# CM33 register map
Registers are 32-bit, read-write, reset 0x0 unless marked. A register's access mark holds for its fields unless they carry their own. Offsets are from the block's base; lines under a group give offsets from that group; [hi:lo] are bit positions; {n}, {i} and the like mark numbered series; 'fields as' and 'values as' point back to an identical list; <NAME> marks a mode.

## Memory map
0xE0001000 DWT size 0x8 — Data Watchpoint and Trace
0xE000E010 SYSTICK size 0x20 — SysTick Timer
0xE000E100 NVIC size 0x380 — Nested Vectored Interrupt Controller
0xE000ED00 SCB size 0x90 — System Control Block
0xE000ED90 MPU size 0x38 — Memory Protection Unit (PMSAv8)
0xE000EDD0 SAU blocks up to offset 0x1C — Security Attribution Unit (fault registers)
0xE000EDF0 DCB size 0x10 — Debug Control Block
0xE000EF34 FP size 0x4 — Floating-Point Extension
0xE000EF50 CMO size 0x2C — Cache Maintenance Operations

## SYSTICK — SysTick Timer
Base 0xE000E010
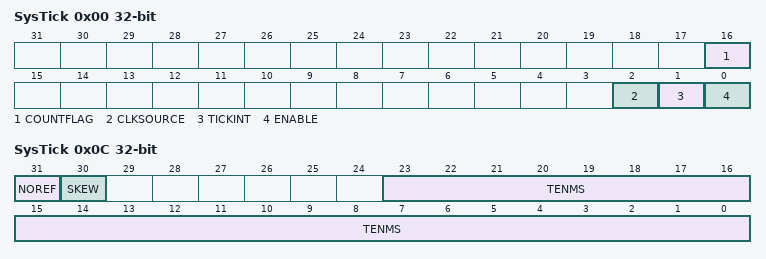
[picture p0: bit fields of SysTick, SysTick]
0x00 SysTick Control and Status Register — Controls the SysTick timer and provides status data for the selected Security state
  [16] COUNTFLAG — Count flag. Indicates whether the counter has counted to zero since the last read of this register
    0=Timer has not counted to 0; 1=Timer has counted to 0
  [2] CLKSOURCE — Clock source. Indicates the SysTick clock source
    0=external (Uses the IMPLEMENTATION DEFINED external reference clock); 1=processor (Uses the PE clock)
  [1] TICKINT — Tick interrupt
    0=interrupt_disabled (Count to 0 does not affect the SysTick exception status); 1=interrupt_enabled (Count to 0 changes the SysTick exception status to pending)
  [0] ENABLE — SysTick enable. Indicates the enabled status of the SysTick counter
    0=Counter is disabled; 1=Counter is operating
0x04 SysTick Reload Value Register — Provides access SysTick timer counter reload value for the selected Security state
  [23:0] RELOAD — Counter reload value
0x08 SysTick Current Value Register — Reads or clears the SysTick timer current counter value for the selected Security state
  [23:0] CURRENT — Reset counter value
0x0C SysTick Calibration Value Register ro — Reads the SysTick timer calibration value and parameters for the selected Security state
  [31] NOREF — No reference. Indicates whether the IMPLEMENTATION DEFINED reference clock is implemented
    0=Reference clock is implemented; 1=Reference clock is not implemented
  [30] SKEW — Skew. Indicates whether the 10ms calibration value is exact
    0=TENMS calibration value is exact; 1=TENMS calibration value is inexact
  [23:0] TENMS — Ten milliseconds

## NVIC — Nested Vectored Interrupt Controller
Base 0xE000E100
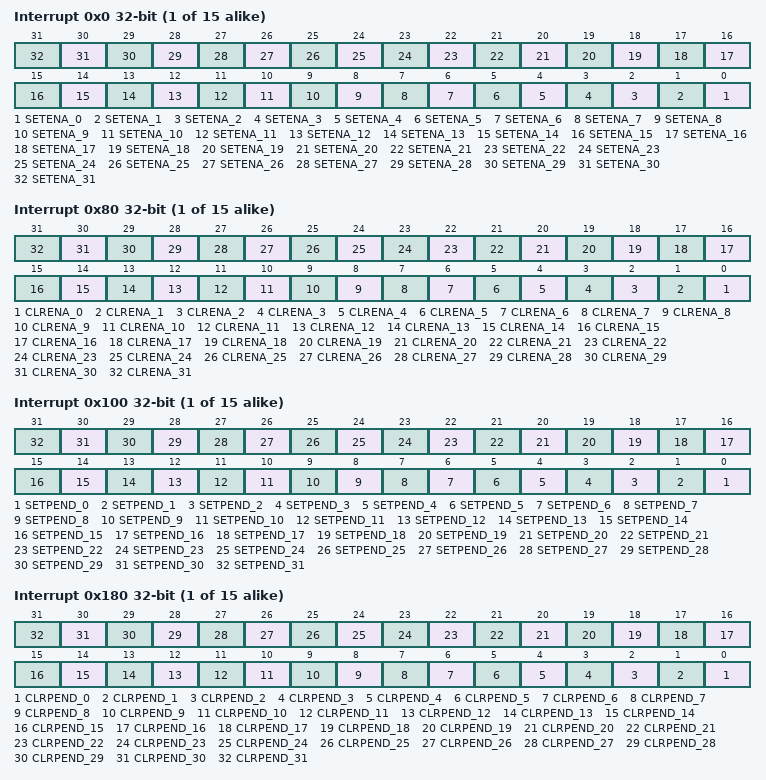
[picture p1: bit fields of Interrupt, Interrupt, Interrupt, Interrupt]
{0x0+4i} Interrupt Set Enable Register {i} (i=0..14) — Enables or reads the enabled state of each group of 32 interrupts
  [n] SETENA_{n} (n=0..31) write-1-sets — Set enable. For SETENA[m] in NVIC_ISERn, allows interrupt to be set enabled
    0=No effect; 1=Enable interrupt
{0x80+4i} Interrupt Clear Enable Register {i} (i=0..14) — Clears or reads the enabled state of each group of 32 interrupts
  [n] CLRENA_{n} (n=0..31) write-1-clears — Clear enable. For CLRENA[m] in NVIC_ICERn, allows interrupt to be disabled
    0=No effect; 1=Disable interrupt
{0x100+4i} Interrupt Set Pending Register {i} (i=0..14) — Enables or reads the pending state of each group of 32 interrupts
  [n] SETPEND_{n} (n=0..31) write-1-sets — Set pending. For SETPEND[m] in NVIC_ISPRn, allows interrupt to be set pending
    0=No effect; 1=Pend interrupt
{0x180+4i} Interrupt Clear Pending Register {i} (i=0..14) — Clears or reads the pending state of each group of 32 interrupts
  [n] CLRPEND_{n} (n=0..31) write-1-clears — Clear pending. For CLRPEND[m] in NVIC_ICPRn, allows interrupt to be unpended
    0=No effect; 1=Clear pending state of interrupt
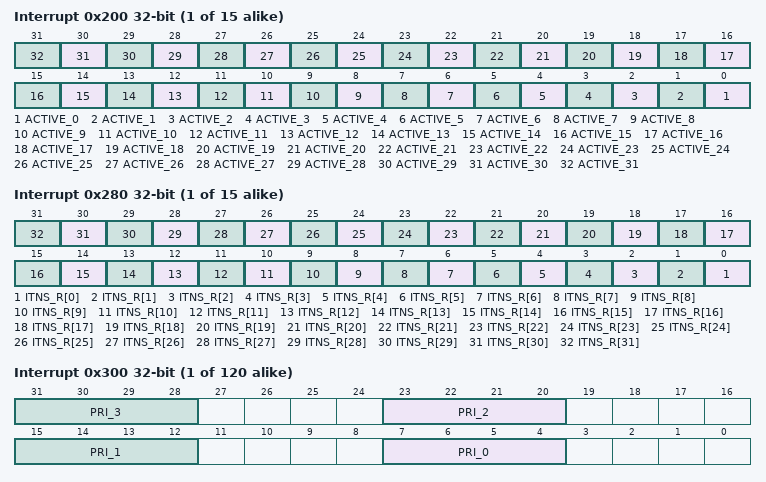
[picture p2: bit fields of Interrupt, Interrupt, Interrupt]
{0x200+4i} Interrupt Active Bit Register {i} (i=0..14) ro — For each group of 32 interrupts, shows the active state of each interrupt
  [n] ACTIVE_{n} (n=0..31) — Active state. For ACTIVE[m] in NVIC_IABRn, indicates the active state for interrupt 32n+m
    0=Interrupt not active; 1=Interrupt is active
{0x280+4i} Interrupt Target Non-secure Register {i} (i=0..14) — For each group of 32 interrupts, determines whether each interrupt targets Non-secure or Secure state
  [n] ITNS_R[{n}] (n=0..31) — Interrupt Targets Non-secure
    0=Interrupt targets Secure state; 1=Interrupt targets Non-secure state
{0x300+4i} Interrupt Priority Register {i} (i=0..119) — Sets or reads interrupt priorities
  [8n+7:8n+4] PRI_{n} (n=0..3) — Priority of interrupt 4n+m. The RP2350's Cortex-M33 implements the top four bits of each byte, [7:4]; the rest read as zero and ignore writes
